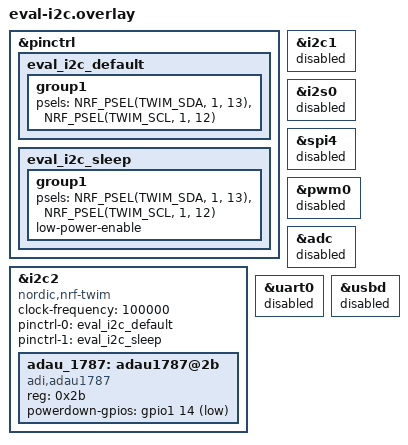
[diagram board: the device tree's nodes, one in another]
#include <zephyr/dt-bindings/pinctrl/nrf-pinctrl.h>
#include <zephyr/dt-bindings/gpio/gpio.h>

/*
 * Use two otherwise unused Arduino-header pins instead of the Audio DK's
 * on-board I2C bus. This avoids its INA231 devices and their local pull-ups.
 *
 *   D9  / P1.13 -> EVAL SDA
 *   D10 / P1.12 -> EVAL SCL
 *   D5  / P1.14 -> EVAL ADAU1787 !PD (J15 open)
 *
 * The ADAU1787 EVAL supplies the only bus pull-ups, referenced to its IOVDD.
 */
&pinctrl {
	eval_i2c_default: eval_i2c_default {
		group1 {
			psels = <NRF_PSEL(TWIM_SDA, 1, 13)>,
				<NRF_PSEL(TWIM_SCL, 1, 12)>;
		};
	};

	eval_i2c_sleep: eval_i2c_sleep {
		group1 {
			psels = <NRF_PSEL(TWIM_SDA, 1, 13)>,
				<NRF_PSEL(TWIM_SCL, 1, 12)>;
			low-power-enable;
		};
	};
};

&i2c2 {
	compatible = "nordic,nrf-twim";
	status = "okay";
	clock-frequency = <100000>;
	pinctrl-0 = <&eval_i2c_default>;
	pinctrl-1 = <&eval_i2c_sleep>;
	pinctrl-names = "default", "sleep";

	adau_1787: adau1787@2b {
		compatible = "adi,adau1787";
		status = "okay";
		reg = <0x2b>;
		powerdown-gpios = <&gpio1 14 GPIO_ACTIVE_LOW>;
	};
};

/* Keep the Audio DK's local peripherals out of this diagnostic image. */
&i2c1 {
	status = "disabled";
};

&i2s0 {
	status = "disabled";
};

&spi4 {
	status = "disabled";
};

&pwm0 {
	status = "disabled";
};

&adc {
	status = "disabled";
};

&uart0 {
	status = "disabled";
};

&usbd {
	status = "disabled";
};
